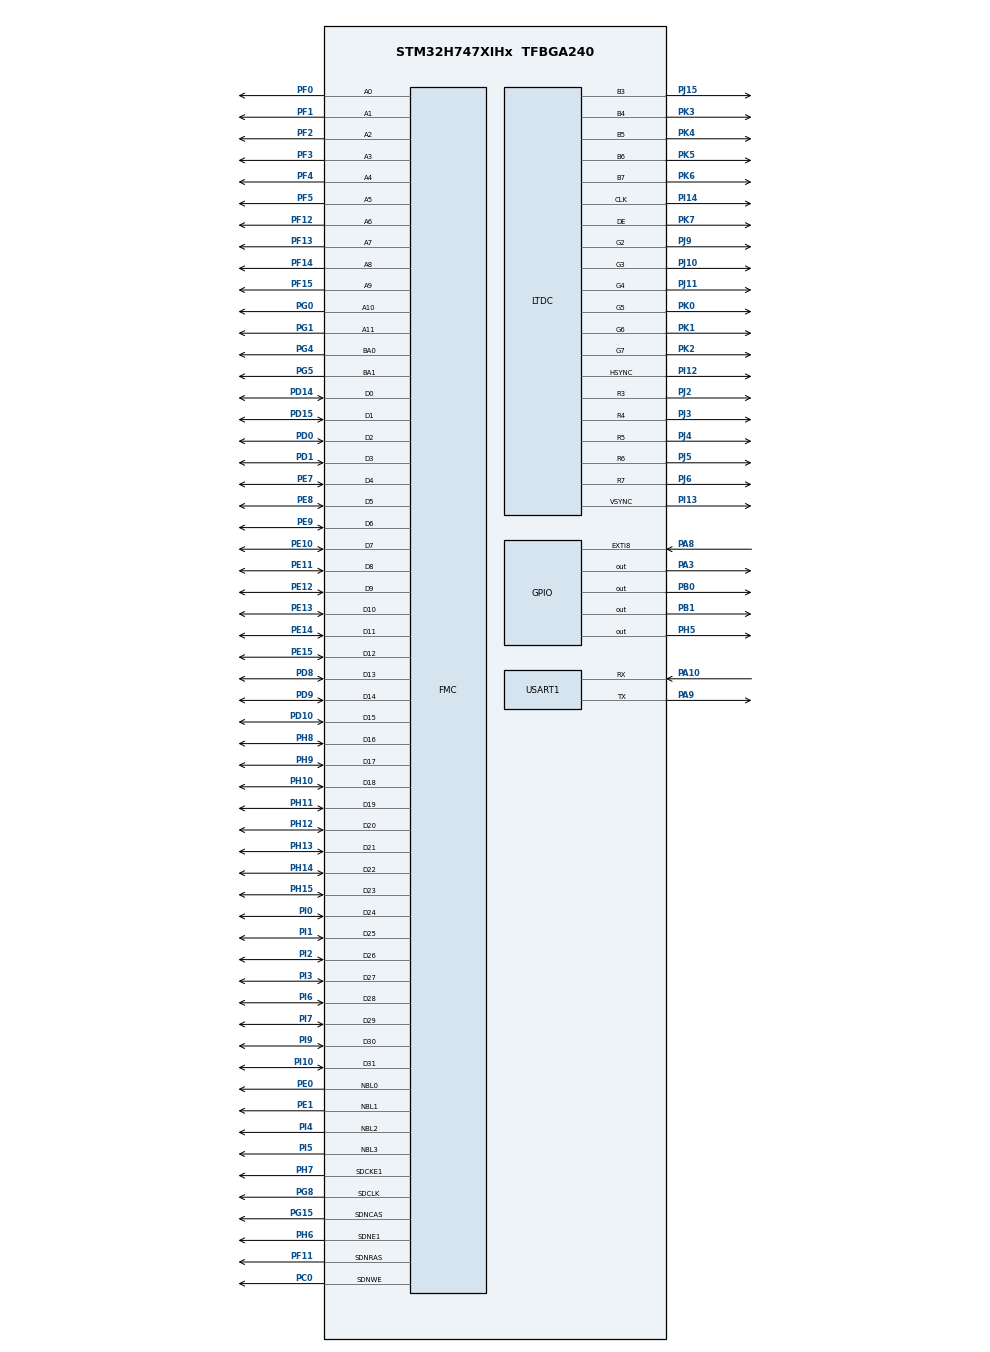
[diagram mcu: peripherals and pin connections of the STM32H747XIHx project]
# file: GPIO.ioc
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CortexM4.IPs=CORTEX_M4\:I,DEBUG,FATFS_M4\:I,FREERTOS_M4\:I,IWDG2\:I,OPENAMP_M4\:I,PDM2PCM_M4\:I,PWR,RCC,RESMGR_UTILITY,SYS_M4\:I,USB_DEVICE_M4\:I,USB_HOST_M4\:I,VREFBUF,WWDG2\:I,GPIO,DMA,BDMA,MDMA,NVIC2\:I
CortexM7.IPs=CORTEX_M7\:I,DEBUG\:I,FATFS_M7\:I,FREERTOS_M7\:I,IWDG1\:I,OPENAMP_M7\:I,PDM2PCM_M7\:I,PWR\:I,RCC\:I,RESMGR_UTILITY\:I,SYS\:I,USB_DEVICE_M7\:I,USB_HOST_M7\:I,VREFBUF\:I,WWDG1\:I,GPIO\:I,DMA\:I,BDMA\:I,MDMA\:I,NVIC1\:I,USART1\:I,FMC\:I,DMA2D\:I,LTDC\:I,DSIHOST\:I
CortexM7.Pins=PA8,PB1,PA3
DMA2D.ColorMode=DMA2D_OUTPUT_RGB565
DMA2D.InputAlphaForeground=255
DMA2D.Mode=DMA2D_M2M
FMC.CASLatency2=FMC_SDRAM_CAS_LATENCY_2
FMC.ColumnBitsNumber2=FMC_SDRAM_COLUMN_BITS_NUM_9
FMC.ExitSelfRefreshDelay2=8
FMC.LoadToActiveDelay2=2
FMC.RCDDelay2=3
FMC.RPDelay2=3
FMC.ReadBurst2=FMC_SDRAM_RBURST_ENABLE
FMC.ReadPipeDelay2=FMC_SDRAM_RPIPE_DELAY_1
FMC.RowCycleDelay2=8
FMC.SDClockPeriod2=FMC_SDRAM_CLOCK_PERIOD_2
FMC.SelfRefreshTime2=6
FMC.WriteRecoveryTime2=3
LTDC.ActiveW=800
LTDC.Alpha_L0=255
LTDC.FBStartAdress_L0=\t 0xD0000000
LTDC.HBP=46
LTDC.HFP=210
LTDC.HSync=1
LTDC.ImageHeight_L0=480
LTDC.ImageWidth_L0=800
LTDC.Layers=0
LTDC.PCPolarity=LTDC_PCPOLARITY_IIPC
LTDC.PixelFormat_L0=LTDC_PIXEL_FORMAT_RGB565
LTDC.VBP=23
LTDC.VFP=22
LTDC.VSync=1
LTDC.WindowX1_L0=799
LTDC.WindowY1_L0=479
Mcu.Family=STM32H7
Mcu.Name=STM32H747XIHx
Mcu.Package=TFBGA240
NVIC1.EXTI9_5_IRQn=true\:0\:0\:false\:false\:true\:true\:true\:true
NVIC1.PriorityGroup=NVIC_PRIORITYGROUP_4
NVIC1.USART1_IRQn=true\:0\:0\:false\:false\:true\:true\:true\:true
NVIC2.PriorityGroup=NVIC_PRIORITYGROUP_4
PA10.Mode=Asynchronous
PA10.PinAttribute=CortexM7
PA10.Signal=USART1_RX
PA3.PinAttribute=CortexM7
PA3.PinState=GPIO_PIN_SET
PA3.Signal=GPIO_Output
PA8.GPIO_PuPd=GPIO_PULLDOWN
PA8.PinAttribute=CortexM7
PA8.Signal=GPXTI8
PA9.Mode=Asynchronous
PA9.PinAttribute=CortexM7
PA9.Signal=USART1_TX
PB0.PinAttribute=Free
PB0.Signal=GPIO_Output
PB1.PinAttribute=CortexM7
PB1.PinState=GPIO_PIN_SET
PB1.Signal=GPIO_Output
PC0.PinAttribute=CortexM7
PC0.Signal=FMC_SDNWE
PD0.PinAttribute=CortexM7
PD0.Signal=FMC_D2_DA2
PD1.PinAttribute=CortexM7
PD1.Signal=FMC_D3_DA3
PD10.PinAttribute=CortexM7
PD10.Signal=FMC_D15_DA15
PD14.PinAttribute=CortexM7
PD14.Signal=FMC_D0_DA0
PD15.PinAttribute=CortexM7
PD15.Signal=FMC_D1_DA1
PD8.PinAttribute=CortexM7
PD8.Signal=FMC_D13_DA13
PD9.PinAttribute=CortexM7
PD9.Signal=FMC_D14_DA14
PE0.PinAttribute=CortexM7
PE0.Signal=FMC_NBL0
PE1.PinAttribute=CortexM7
PE1.Signal=FMC_NBL1
PE10.PinAttribute=CortexM7
PE10.Signal=FMC_D7_DA7
PE11.PinAttribute=CortexM7
PE11.Signal=FMC_D8_DA8
PE12.PinAttribute=CortexM7
PE12.Signal=FMC_D9_DA9
PE13.PinAttribute=CortexM7
PE13.Signal=FMC_D10_DA10
PE14.PinAttribute=CortexM7
PE14.Signal=FMC_D11_DA11
PE15.PinAttribute=CortexM7
PE15.Signal=FMC_D12_DA12
PE7.PinAttribute=CortexM7
PE7.Signal=FMC_D4_DA4
PE8.PinAttribute=CortexM7
PE8.Signal=FMC_D5_DA5
PE9.PinAttribute=CortexM7
PE9.Signal=FMC_D6_DA6
PF0.PinAttribute=CortexM7
PF0.Signal=FMC_A0
PF1.PinAttribute=CortexM7
PF1.Signal=FMC_A1
PF11.PinAttribute=CortexM7
PF11.Signal=FMC_SDNRAS
PF12.PinAttribute=CortexM7
PF12.Signal=FMC_A6
PF13.PinAttribute=CortexM7
PF13.Signal=FMC_A7
PF14.PinAttribute=CortexM7
PF14.Signal=FMC_A8
PF15.PinAttribute=CortexM7
PF15.Signal=FMC_A9
PF2.PinAttribute=CortexM7
PF2.Signal=FMC_A2
PF3.PinAttribute=CortexM7
PF3.Signal=FMC_A3
PF4.PinAttribute=CortexM7
PF4.Signal=FMC_A4
PF5.PinAttribute=CortexM7
PF5.Signal=FMC_A5
PG0.PinAttribute=CortexM7
PG0.Signal=FMC_A10
PG1.PinAttribute=CortexM7
PG1.Signal=FMC_A11
PG15.PinAttribute=CortexM7
PG15.Signal=FMC_SDNCAS
PG4.PinAttribute=CortexM7
PG4.Signal=FMC_A14_BA0
PG5.PinAttribute=CortexM7
PG5.Signal=FMC_A15_BA1
PG8.PinAttribute=CortexM7
PG8.Signal=FMC_SDCLK
PH0-OSC_IN\ (PH0).Mode=HSE-External-Oscillator
PH0-OSC_IN\ (PH0).PinAttribute=Free
PH0-OSC_IN\ (PH0).Signal=RCC_OSC_IN
PH1-OSC_OUT\ (PH1).Mode=HSE-External-Oscillator
PH1-OSC_OUT\ (PH1).PinAttribute=Free
PH1-OSC_OUT\ (PH1).Signal=RCC_OSC_OUT
PH10.PinAttribute=CortexM7
PH10.Signal=FMC_D18
PH11.PinAttribute=CortexM7
PH11.Signal=FMC_D19
PH12.PinAttribute=CortexM7
PH12.Signal=FMC_D20
PH13.PinAttribute=CortexM7
PH13.Signal=FMC_D21
PH14.PinAttribute=CortexM7
PH14.Signal=FMC_D22
PH15.PinAttribute=CortexM7
PH15.Signal=FMC_D23
PH5.PinAttribute=Free
PH5.Signal=GPIO_Output
PH6.Mode=SdramChipSelect2_2
PH6.PinAttribute=CortexM7
PH6.Signal=FMC_SDNE1
PH7.Mode=SdramChipSelect2_2
PH7.PinAttribute=CortexM7
PH7.Signal=FMC_SDCKE1
PH8.PinAttribute=CortexM7
PH8.Signal=FMC_D16
PH9.PinAttribute=CortexM7
PH9.Signal=FMC_D17
PI0.PinAttribute=CortexM7
PI0.Signal=FMC_D24
PI1.PinAttribute=CortexM7
PI1.Signal=FMC_D25
PI10.PinAttribute=CortexM7
PI10.Signal=FMC_D31
PI12.GPIO_Speed=GPIO_SPEED_FREQ_VERY_HIGH
PI12.Mode=RGB565
PI12.PinAttribute=CortexM7
PI12.Signal=LTDC_HSYNC
PI13.GPIO_Speed=GPIO_SPEED_FREQ_VERY_HIGH
PI13.Mode=RGB565
PI13.PinAttribute=CortexM7
PI13.Signal=LTDC_VSYNC
PI14.GPIO_Speed=GPIO_SPEED_FREQ_VERY_HIGH
PI14.Mode=RGB565
PI14.PinAttribute=CortexM7
PI14.Signal=LTDC_CLK
PI2.PinAttribute=CortexM7
PI2.Signal=FMC_D26
PI3.PinAttribute=CortexM7
PI3.Signal=FMC_D27
PI4.PinAttribute=CortexM7
PI4.Signal=FMC_NBL2
PI5.PinAttribute=CortexM7
PI5.Signal=FMC_NBL3
PI6.PinAttribute=CortexM7
PI6.Signal=FMC_D28
PI7.PinAttribute=CortexM7
PI7.Signal=FMC_D29
PI9.PinAttribute=CortexM7
PI9.Signal=FMC_D30
PJ10.GPIO_Speed=GPIO_SPEED_FREQ_VERY_HIGH
PJ10.Mode=RGB565
PJ10.PinAttribute=CortexM7
PJ10.Signal=LTDC_G3
PJ11.GPIO_Speed=GPIO_SPEED_FREQ_VERY_HIGH
PJ11.Mode=RGB565
PJ11.PinAttribute=CortexM7
PJ11.Signal=LTDC_G4
PJ15.GPIO_Speed=GPIO_SPEED_FREQ_VERY_HIGH
PJ15.Mode=RGB565
PJ15.PinAttribute=CortexM7
PJ15.Signal=LTDC_B3
PJ2.GPIO_Speed=GPIO_SPEED_FREQ_VERY_HIGH
PJ2.Mode=RGB565
PJ2.PinAttribute=CortexM7
PJ2.Signal=LTDC_R3
PJ3.GPIO_Speed=GPIO_SPEED_FREQ_VERY_HIGH
PJ3.Mode=RGB565
PJ3.PinAttribute=CortexM7
PJ3.Signal=LTDC_R4
PJ4.GPIO_Speed=GPIO_SPEED_FREQ_VERY_HIGH
PJ4.Mode=RGB565
PJ4.PinAttribute=CortexM7
PJ4.Signal=LTDC_R5
PJ5.GPIO_Speed=GPIO_SPEED_FREQ_VERY_HIGH
PJ5.Mode=RGB565
PJ5.PinAttribute=CortexM7
PJ5.Signal=LTDC_R6
PJ6.GPIO_Speed=GPIO_SPEED_FREQ_VERY_HIGH
PJ6.Mode=RGB565
PJ6.PinAttribute=CortexM7
PJ6.Signal=LTDC_R7
PJ9.GPIO_Speed=GPIO_SPEED_FREQ_VERY_HIGH
PJ9.Mode=RGB565
PJ9.PinAttribute=CortexM7
PJ9.Signal=LTDC_G2
PK0.GPIO_Speed=GPIO_SPEED_FREQ_VERY_HIGH
PK0.Mode=RGB565
PK0.PinAttribute=CortexM7
PK0.Signal=LTDC_G5
PK1.GPIO_Speed=GPIO_SPEED_FREQ_VERY_HIGH
PK1.Mode=RGB565
PK1.PinAttribute=CortexM7
PK1.Signal=LTDC_G6
PK2.GPIO_Speed=GPIO_SPEED_FREQ_VERY_HIGH
PK2.Mode=RGB565
PK2.PinAttribute=CortexM7
PK2.Signal=LTDC_G7
PK3.GPIO_Speed=GPIO_SPEED_FREQ_VERY_HIGH
PK3.Mode=RGB565
PK3.PinAttribute=CortexM7
PK3.Signal=LTDC_B4
PK4.GPIO_Speed=GPIO_SPEED_FREQ_VERY_HIGH
PK4.Mode=RGB565
PK4.PinAttribute=CortexM7
PK4.Signal=LTDC_B5
PK5.GPIO_Speed=GPIO_SPEED_FREQ_VERY_HIGH
PK5.Mode=RGB565
PK5.PinAttribute=CortexM7
PK5.Signal=LTDC_B6
PK6.GPIO_Speed=GPIO_SPEED_FREQ_VERY_HIGH
PK6.Mode=RGB565
PK6.PinAttribute=CortexM7
PK6.Signal=LTDC_B7
PK7.GPIO_Speed=GPIO_SPEED_FREQ_VERY_HIGH
PK7.Mode=RGB565
PK7.PinAttribute=CortexM7
PK7.Signal=LTDC_DE
ProjectManager.HeapSize=M4-0x200,M7-0x200
ProjectManager.StackSize=M4-0x400,M7-0x400
ProjectManager.TargetToolchain=Makefile
RCC.ADCFreq_Value=129000000
RCC.APB1Freq_Value=120000000
RCC.APB2Freq_Value=120000000
RCC.APB3Freq_Value=120000000
RCC.APB4Freq_Value=120000000
RCC.CortexFreq_Value=480000000
RCC.D1PPRE=RCC_APB3_DIV2
RCC.D2PPRE1=RCC_APB1_DIV2
RCC.D2PPRE2=RCC_APB2_DIV2
RCC.D3PPRE=RCC_APB4_DIV2
RCC.DIVM1=4
RCC.DIVN1=60
RCC.HCLKFreq_Value=240000000
RCC.HPRE=RCC_HCLK_DIV2
RCC.PLL2FRACN=0
RCC.PLL3FRACN=0
RCC.PLLFRACN=0
RCC.SYSCLKFreq_VALUE=480000000
RCC.SYSCLKSource=RCC_SYSCLKSOURCE_PLLCLK
RCC.USBFreq_Value=480000000
SH.FMC_A0.0=FMC_A0,12b-sda2
SH.FMC_A1.0=FMC_A1,12b-sda2
SH.FMC_A10.0=FMC_A10,12b-sda2
SH.FMC_A11.0=FMC_A11,12b-sda2
SH.FMC_A14_BA0.0=FMC_BA0,FourSdramBanks2
SH.FMC_A15_BA1.0=FMC_BA1,FourSdramBanks2
SH.FMC_A2.0=FMC_A2,12b-sda2
SH.FMC_A3.0=FMC_A3,12b-sda2
SH.FMC_A4.0=FMC_A4,12b-sda2
SH.FMC_A5.0=FMC_A5,12b-sda2
SH.FMC_A6.0=FMC_A6,12b-sda2
SH.FMC_A7.0=FMC_A7,12b-sda2
SH.FMC_A8.0=FMC_A8,12b-sda2
SH.FMC_A9.0=FMC_A9,12b-sda2
SH.FMC_D0_DA0.0=FMC_D0,sd-32b-d2
SH.FMC_D10_DA10.0=FMC_D10,sd-32b-d2
SH.FMC_D11_DA11.0=FMC_D11,sd-32b-d2
SH.FMC_D12_DA12.0=FMC_D12,sd-32b-d2
SH.FMC_D13_DA13.0=FMC_D13,sd-32b-d2
SH.FMC_D14_DA14.0=FMC_D14,sd-32b-d2
SH.FMC_D15_DA15.0=FMC_D15,sd-32b-d2
SH.FMC_D16.0=FMC_D16,sd-32b-d2
SH.FMC_D17.0=FMC_D17,sd-32b-d2
SH.FMC_D18.0=FMC_D18,sd-32b-d2
SH.FMC_D19.0=FMC_D19,sd-32b-d2
SH.FMC_D1_DA1.0=FMC_D1,sd-32b-d2
SH.FMC_D20.0=FMC_D20,sd-32b-d2
SH.FMC_D21.0=FMC_D21,sd-32b-d2
SH.FMC_D22.0=FMC_D22,sd-32b-d2
SH.FMC_D23.0=FMC_D23,sd-32b-d2
SH.FMC_D24.0=FMC_D24,sd-32b-d2
SH.FMC_D25.0=FMC_D25,sd-32b-d2
SH.FMC_D26.0=FMC_D26,sd-32b-d2
SH.FMC_D27.0=FMC_D27,sd-32b-d2
SH.FMC_D28.0=FMC_D28,sd-32b-d2
SH.FMC_D29.0=FMC_D29,sd-32b-d2
SH.FMC_D2_DA2.0=FMC_D2,sd-32b-d2
SH.FMC_D30.0=FMC_D30,sd-32b-d2
SH.FMC_D31.0=FMC_D31,sd-32b-d2
SH.FMC_D3_DA3.0=FMC_D3,sd-32b-d2
SH.FMC_D4_DA4.0=FMC_D4,sd-32b-d2
SH.FMC_D5_DA5.0=FMC_D5,sd-32b-d2
SH.FMC_D6_DA6.0=FMC_D6,sd-32b-d2
SH.FMC_D7_DA7.0=FMC_D7,sd-32b-d2
SH.FMC_D8_DA8.0=FMC_D8,sd-32b-d2
SH.FMC_D9_DA9.0=FMC_D9,sd-32b-d2
SH.FMC_NBL0.0=FMC_NBL0,Sd4ByteEnable2
SH.FMC_NBL1.0=FMC_NBL1,Sd4ByteEnable2
SH.FMC_NBL2.0=FMC_NBL2,Sd4ByteEnable2
SH.FMC_NBL3.0=FMC_NBL3,Sd4ByteEnable2
SH.FMC_SDCLK.0=FMC_SDCLK,12b-sda2
SH.FMC_SDNCAS.0=FMC_SDNCAS,12b-sda2
SH.FMC_SDNRAS.0=FMC_SDNRAS,12b-sda2
SH.FMC_SDNWE.0=FMC_SDNWE,12b-sda2
SYS.userName=SYS_M7
USART1.VirtualMode-Asynchronous=VM_ASYNC
VP_DMA2D_VS_DMA2D.Mode=DMA2D_Activate
VP_SYS_M4_VS_Systick.Mode=SysTick
board=custom

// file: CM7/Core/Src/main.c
/* USER CODE BEGIN Header */
/**
  ******************************************************************************
  * @file           : main.c
  * @brief          : Main program body
  ******************************************************************************
  * @attention
  *
  * Copyright (c) 2026 STMicroelectronics.
  * All rights reserved.
  *
  * This software is licensed under terms that can be found in the LICENSE file
  * in the root directory of this software component.
  * If no LICENSE file comes with this software, it is provided AS-IS.
  *
  ******************************************************************************
  */
/* USER CODE END Header */
#include "main.h"
#include "dma2d.h"
#include "ltdc.h"
#include "usart.h"
#include "gpio.h"
#include "fmc.h"

/* USER CODE BEGIN Includes */
#include "bsp_sys.h"
#include "app_rgb_touch.h"
/* USER CODE END Includes */

/* USER CODE BEGIN PD */

#ifndef HSEM_ID_0
#define HSEM_ID_0 (0U) /* HW semaphore 0*/
#endif

/* USER CODE END PD */

void SystemClock_Config(void);

/* USER CODE BEGIN 0 */
/*
 * CubeMX 每次 Generate 后请只保留：
 *   Includes: bsp_sys.h + app_rgb_touch.h
 *   1:        bsp_cache_enable()
 *   2:        app_rgb_touch_start();
 *   3:        （保持为空，勿写代码�??
 * 触摸逻辑�?? app_rgb_touch.c，勿�?? USER CODE 3 里加 poll/while�??
 */
/* USER CODE END 0 */

int main(void)
{
  /* USER CODE BEGIN 1 */
  bsp_cache_enable();
  /* USER CODE END 1 */
/* USER CODE BEGIN Boot_Mode_Sequence_0 */
  int32_t timeout;
/* USER CODE END Boot_Mode_Sequence_0 */

/* USER CODE BEGIN Boot_Mode_Sequence_1 */
  /* Wait until CPU2 boots and enters in stop mode or timeout*/
  timeout = 0xFFFF;
  while((__HAL_RCC_GET_FLAG(RCC_FLAG_D2CKRDY) != RESET) && (timeout-- > 0));
  if ( timeout < 0 )
  {
  Error_Handler();
  }
/* USER CODE END Boot_Mode_Sequence_1 */
  /* MCU Configuration--------------------------------------------------------*/

  /* Reset of all peripherals, Initializes the Flash interface and the Systick. */
  HAL_Init();

  /* Configure the system clock */
  SystemClock_Config();
/* USER CODE BEGIN Boot_Mode_Sequence_2 */
/* When system initialization is finished, Cortex-M7 will release Cortex-M4 by means of
HSEM notification */
/*HW semaphore Clock enable*/
__HAL_RCC_HSEM_CLK_ENABLE();
/*Take HSEM */
HAL_HSEM_FastTake(HSEM_ID_0);
/*Release HSEM in order to notify the CPU2(CM4)*/
HAL_HSEM_Release(HSEM_ID_0,0);
/* wait until CPU2 wakes up from stop mode */
timeout = 0xFFFF;
while((__HAL_RCC_GET_FLAG(RCC_FLAG_D2CKRDY) == RESET) && (timeout-- > 0));
if ( timeout < 0 )
{
Error_Handler();
}
/* USER CODE END Boot_Mode_Sequence_2 */

  /* Initialize all configured peripherals */
  MX_GPIO_Init();
  MX_USART1_UART_Init();
  MX_FMC_Init();
  MX_LTDC_Init();
  MX_DMA2D_Init();
  /* USER CODE BEGIN 2 */
  app_rgb_touch_init();
  /* USER CODE END 2 */

  /* Infinite loop */
  while (1)
  {

    /* USER CODE BEGIN 3 */
    app_rgb_touch_poll();
    /* USER CODE END 3 */
  }
}

void SystemClock_Config(void)
{
  RCC_OscInitTypeDef RCC_OscInitStruct = {0};
  RCC_ClkInitTypeDef RCC_ClkInitStruct = {0};

  /** Supply configuration update enable
  */
  HAL_PWREx_ConfigSupply(PWR_LDO_SUPPLY);

  /** Configure the main internal regulator output voltage
  */
  __HAL_PWR_VOLTAGESCALING_CONFIG(PWR_REGULATOR_VOLTAGE_SCALE1);

  while(!__HAL_PWR_GET_FLAG(PWR_FLAG_VOSRDY)) {}

  __HAL_RCC_SYSCFG_CLK_ENABLE();
  __HAL_PWR_VOLTAGESCALING_CONFIG(PWR_REGULATOR_VOLTAGE_SCALE0);

  while(!__HAL_PWR_GET_FLAG(PWR_FLAG_VOSRDY)) {}

  /** Initializes the RCC Oscillators according to the specified parameters
  * in the RCC_OscInitTypeDef structure.
  */
  RCC_OscInitStruct.OscillatorType = RCC_OSCILLATORTYPE_HSI;
  RCC_OscInitStruct.HSIState = RCC_HSI_DIV1;
  RCC_OscInitStruct.HSICalibrationValue = RCC_HSICALIBRATION_DEFAULT;
  RCC_OscInitStruct.PLL.PLLState = RCC_PLL_ON;
  RCC_OscInitStruct.PLL.PLLSource = RCC_PLLSOURCE_HSI;
  RCC_OscInitStruct.PLL.PLLM = 4;
  RCC_OscInitStruct.PLL.PLLN = 60;
  RCC_OscInitStruct.PLL.PLLP = 2;
  RCC_OscInitStruct.PLL.PLLQ = 2;
  RCC_OscInitStruct.PLL.PLLR = 2;
  RCC_OscInitStruct.PLL.PLLRGE = RCC_PLL1VCIRANGE_3;
  RCC_OscInitStruct.PLL.PLLVCOSEL = RCC_PLL1VCOWIDE;
  RCC_OscInitStruct.PLL.PLLFRACN = 0;
  if (HAL_RCC_OscConfig(&RCC_OscInitStruct) != HAL_OK)
  {
    Error_Handler();
  }

  /** Initializes the CPU, AHB and APB buses clocks
  */
  RCC_ClkInitStruct.ClockType = RCC_CLOCKTYPE_HCLK|RCC_CLOCKTYPE_SYSCLK
                              |RCC_CLOCKTYPE_PCLK1|RCC_CLOCKTYPE_PCLK2
                              |RCC_CLOCKTYPE_D3PCLK1|RCC_CLOCKTYPE_D1PCLK1;
  RCC_ClkInitStruct.SYSCLKSource = RCC_SYSCLKSOURCE_PLLCLK;
  RCC_ClkInitStruct.SYSCLKDivider = RCC_SYSCLK_DIV1;
  RCC_ClkInitStruct.AHBCLKDivider = RCC_HCLK_DIV2;
  RCC_ClkInitStruct.APB3CLKDivider = RCC_APB3_DIV2;
  RCC_ClkInitStruct.APB1CLKDivider = RCC_APB1_DIV2;
  RCC_ClkInitStruct.APB2CLKDivider = RCC_APB2_DIV2;
  RCC_ClkInitStruct.APB4CLKDivider = RCC_APB4_DIV2;

  if (HAL_RCC_ClockConfig(&RCC_ClkInitStruct, FLASH_LATENCY_4) != HAL_OK)
  {
    Error_Handler();
  }
}

void Error_Handler(void)
{
  __disable_irq();
  while (1)
  {
  }
}
